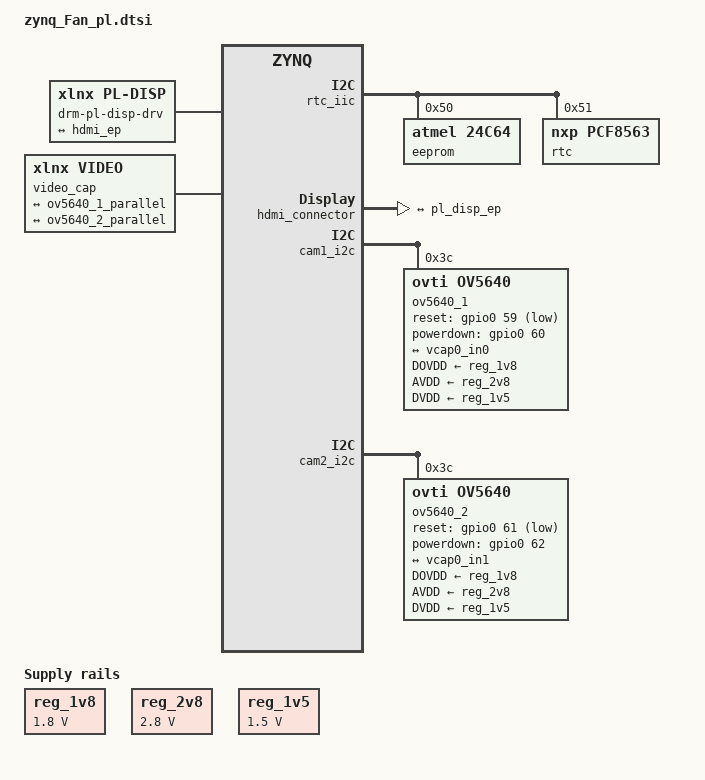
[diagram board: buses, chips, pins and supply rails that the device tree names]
/*
 * CAUTION: This file is automatically generated by Xilinx.
 * Version:  
 * Today is: Thu Jan 21 20:34:55 2021
 */

#include <dt-bindings/gpio/gpio.h>

/ {
	amba_pl: amba_pl {
		#address-cells = <1>;
		#size-cells = <1>;
		compatible = "simple-bus";
		ranges ;
        
        rtc_iic: i2c@41620000 {
			#address-cells = <1>;
			#size-cells = <0>;
			clock-names = "s_axi_aclk";
			clocks = <&clkc 15>;
			compatible = "xlnx,axi-iic-2.0", "xlnx,xps-iic-2.00.a";
			interrupt-names = "iic2intc_irpt";
			interrupt-parent = <&intc>;
			interrupts = <0 31 4>;
			reg = <0x41620000 0x10000>;
            
            eeprom@50{
                compatible = "atmel,24c64";
                reg = <0x50>;
                pagesize = <32>;
            };

            rtc@51{
                compatible = "nxp,pcf8563";
                reg = <0x51>;
            };
		};
             		
  /*  Video Out  */  
        v_frmbuf_rd: v_frmbuf_rd@43c40000 {
			#dma-cells = <1>;
			clock-names = "ap_clk";
			clocks = <&clkc 16>;
			compatible = "xlnx,v-frmbuf-rd-2.1", "xlnx,axi-frmbuf-rd-v2.1";
			interrupt-names = "interrupt";
			interrupt-parent = <&intc>;
			interrupts = <0 29 4>;
			reg = <0x43c30000 0x10000>;
			xlnx,dma-addr-width = <32>;
			xlnx,dma-align = <8>;
			xlnx,max-height = <1080>;
			xlnx,max-width = <1920>;
			xlnx,pixels-per-clock = <1>;
			xlnx,s-axi-ctrl-addr-width = <0x7>;
			xlnx,s-axi-ctrl-data-width = <0x20>;
			xlnx,vid-formats = "rgb888", "xbgr8888", "xrgb8888", "bgr888", "vuy888", "xvuy8888", "yuyv";
			xlnx,video-width = <8>;
            reset-gpios = <&gpio0 54 1>;
		};

        axi_dynclk: axi_dynclk@43c00000 {			
			compatible = "digilent,axi-dynclk";
			reg = <0x43c00000 0x10000>;
            #clock-cells = <0>;
            clock-names = "REF_CLK_I", "s00_axi_aclk";
			clocks = <&clkc 15>, <&clkc 15>;
			clock-output-names = "pixel-clk";
		};
        
        v_tc_0: v_tc@43c10000 {
			clock-names = "clk", "s_axi_aclk";
			clocks = <&axi_dynclk>, <&clkc 15>;
			//compatible = "xlnx,v-tc-6.2", "xlnx,v-tc-6.1";
            compatible = "xlnx,bridge-v-tc-6.1";
			interrupt-names = "irq";
			interrupt-parent = <&intc>;
			interrupts = <0 30 4>;
			reg = <0x43c40000 0x10000>;
            xlnx,pixels-per-clock = <1>;
			xlnx,generator ;
		};
        
        hdmi_connector:hdmi_connector {
            compatible = "fan,pl-hdmi";
            pl_hdmi,edid-i2c = <&i2c1>;		
            //hdmi-hpd-gpios = <&gpio0 57 GPIO_ACTIVE_HIGH>;
            hdmi-oe-gpios = <&gpio0 58 GPIO_ACTIVE_HIGH>;
            ports {
                #address-cells = <1>;
                #size-cells = <0>;
                encoder_hdmi_port: port@0 {
                    reg = <0>;
                    hdmi_ep: endpoint {
                        remote-endpoint = <&pl_disp_ep>;
                    };
                };
            };
        };
        
        drm-pl-disp-drv {
            compatible = "xlnx,pl-disp";
            dmas = <&v_frmbuf_rd 0>;
            dma-names = "dma0";
            xlnx,bridge = <&v_tc_0>;
			//xlnx,vformat = "RG24";
            xlnx,vformat = "XR24";
            #address-cells = <1>;
            #size-cells = <0>;
            pl_disp_port: port@0 {
                reg = <0>;
                pl_disp_ep: endpoint {
                    remote-endpoint = <&hdmi_ep>;
                };
            };
        };
        
   /* Media ov5640 dual camera  */     
        ov5640_clk: ov5640_clk {
			#clock-cells = <0>;
			clock-frequency = <24000000>;
			compatible = "fixed-clock";
		};
        
        reg_1v8: regulator-1v8 {
            compatible = "regulator-fixed";
            regulator-name = "1v8";
            regulator-min-microvolt = <1800000>;
            regulator-max-microvolt = <1800000>;
            regulator-always-on;
        };
        reg_2v8: regulator-2v8 {
            compatible = "regulator-fixed";
            regulator-name = "2v8";
            regulator-min-microvolt = <2800000>;
            regulator-max-microvolt = <2800000>;
            regulator-always-on;
        };
        reg_1v5: regulator-1v5 {
            compatible = "regulator-fixed";
            regulator-name = "1v5";
            regulator-min-microvolt = <1500000>;
            regulator-max-microvolt = <1500000>;
            regulator-always-on;
        };
        
		cam1_i2c: i2c@41600000 {
			#address-cells = <1>;
			#size-cells = <0>;
			clock-names = "s_axi_aclk";
			clocks = <&clkc 15>;
			compatible = "xlnx,axi-iic-2.0", "xlnx,xps-iic-2.00.a";
			interrupt-names = "iic2intc_irpt";
			interrupt-parent = <&intc>;
			interrupts = <0 34 4>;
			reg = <0x41600000 0x10000>;
            
            ov5640_1: camera@3c {
                compatible = "ovti,ov5640";
                //pinctrl-names = "default";
                //pinctrl-0 = <&pinctrl_ov5640>;
                reg = <0x3c>;
                clocks = <&ov5640_clk>;
                clock-names = "xclk";
                DOVDD-supply = <&reg_1v8>; /* 1.8v */
                AVDD-supply = <&reg_2v8>;  /* 2.8v */
                DVDD-supply = <&reg_1v5>;  /* 1.5v */
                
                reset-gpios = <&gpio0 59 GPIO_ACTIVE_LOW>;
                powerdown-gpios = <&gpio0 60 GPIO_ACTIVE_HIGH>;
          
                rotation = <0>;

                port {
                    /* Parallel bus endpoint */
                    ov5640_1_parallel: endpoint {
                        remote-endpoint = <&vcap0_in0>;
                        bus-width = <8>;
                        data-shift = <2>; /* lines 9:2 are used */
                        hsync-active = <0>;
                        vsync-active = <0>;
                        pclk-sample = <1>;
                    };
                };
            };
		};
        
		cam2_i2c: i2c@41610000 {
			#address-cells = <1>;
			#size-cells = <0>;
			clock-names = "s_axi_aclk";
			clocks = <&clkc 15>;
			compatible = "xlnx,axi-iic-2.0", "xlnx,xps-iic-2.00.a";
			interrupt-names = "iic2intc_irpt";
			interrupt-parent = <&intc>;
			interrupts = <0 35 4>;
			reg = <0x41610000 0x10000>;
            
            ov5640_2: camera@3c {
                compatible = "ovti,ov5640";
                //pinctrl-names = "default";
                //pinctrl-0 = <&pinctrl_ov5640>;
                reg = <0x3c>;
                clocks = <&ov5640_clk>;
                clock-names = "xclk";
                DOVDD-supply = <&reg_1v8>; /* 1.8v */
                AVDD-supply = <&reg_2v8>;  /* 2.8v */
                DVDD-supply = <&reg_1v5>;  /* 1.5v */
                
                reset-gpios = <&gpio0 61 GPIO_ACTIVE_LOW>;
                powerdown-gpios = <&gpio0 62 GPIO_ACTIVE_HIGH>;
                
                rotation = <0>;

                port {
                    /* Parallel bus endpoint */
                    ov5640_2_parallel: endpoint {
                        remote-endpoint = <&vcap0_in1>;
                        bus-width = <8>;
                        data-shift = <2>; /* lines 9:2 are used */
                        hsync-active = <0>;
                        vsync-active = <0>;
                        pclk-sample = <1>;
                    };
                };
            };
		};

        fb_video_in_1: v_frmbuf_wr@43c20000 {
			#dma-cells = <1>;
			clock-names = "ap_clk";
			clocks = <&clkc 16>;
			compatible = "xlnx,v-frmbuf-wr-2.1", "xlnx,axi-frmbuf-wr-v2.1";
			interrupt-names = "interrupt";
			interrupt-parent = <&intc>;
			interrupts = <0 32 4>;
			reg = <0x43c10000 0x10000>;
			xlnx,dma-addr-width = <32>;
			xlnx,dma-align = <8>;
			xlnx,max-height = <1944>;
			xlnx,max-width = <2592>;
			xlnx,pixels-per-clock = <1>;
			xlnx,s-axi-ctrl-addr-width = <0x7>;
			xlnx,s-axi-ctrl-data-width = <0x20>;
			xlnx,vid-formats = "rgb888", "bgr888", "xbgr8888", "xrgb8888", "vuy888", "xvuy8888", "yuyv";
			xlnx,video-width = <8>;
            reset-gpios = <&gpio0 55 1>;
		};

		fb_video_in_2: v_frmbuf_wr@43c30000 {
			#dma-cells = <1>;
			clock-names = "ap_clk";
			clocks = <&clkc 16>;
			compatible = "xlnx,v-frmbuf-wr-2.1", "xlnx,axi-frmbuf-wr-v2.1";
			interrupt-names = "interrupt";
			interrupt-parent = <&intc>;
			interrupts = <0 33 4>;
			reg = <0x43c20000 0x10000>;
			xlnx,dma-addr-width = <32>;
			xlnx,dma-align = <8>;
			xlnx,max-height = <1944>;
			xlnx,max-width = <2592>;
			xlnx,pixels-per-clock = <1>;
			xlnx,s-axi-ctrl-addr-width = <0x7>;
			xlnx,s-axi-ctrl-data-width = <0x20>;
			xlnx,vid-formats = "rgb888", "bgr888", "xbgr8888", "xrgb8888", "vuy888", "xvuy8888", "yuyv";
			xlnx,video-width = <8>;
            reset-gpios = <&gpio0 56 1>;
		};
        
        video_cap {
            compatible = "xlnx,video";
            dmas = <&fb_video_in_1 0>, <&fb_video_in_2 0>;
            dma-names = "port0", "port1";

            ports {
                #address-cells = <1>;
                #size-cells = <0>;

                port@0 {
                    reg = <0>;
                    direction = "input";
                    vcap0_in0: endpoint {
                        remote-endpoint = <&ov5640_1_parallel>;
                    };
                };
                port@1 {
                    reg = <1>;
                    direction = "input";
                    vcap0_in1: endpoint {
                        remote-endpoint = <&ov5640_2_parallel>;
                    };
                };
            };
        };

	};

};
